VERSION ""

NS_ :

BS_:

BU_:

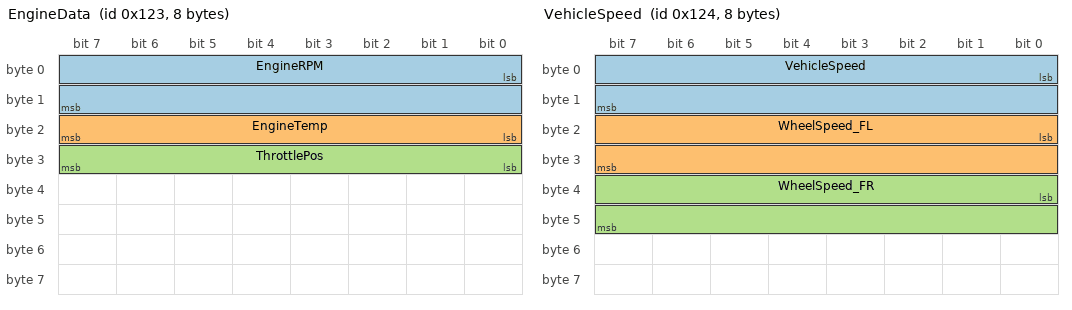
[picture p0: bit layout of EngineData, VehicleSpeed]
BO_ 291 EngineData: 8 Vector__XXX
 SG_ EngineRPM : 0|16@1+ (0.25,0) [0|16383.75] "rpm" Vector__XXX
 SG_ EngineTemp : 16|8@1+ (0.75,-40) [-40|148.75] "degC" Vector__XXX
 SG_ ThrottlePos : 24|8@1+ (0.392157,0) [0|100] "%" Vector__XXX

BO_ 292 VehicleSpeed: 8 Vector__XXX
 SG_ VehicleSpeed : 0|16@1+ (0.01,0) [0|655.35] "km/h" Vector__XXX
 SG_ WheelSpeed_FL : 16|16@1+ (0.01,0) [0|655.35] "km/h" Vector__XXX
 SG_ WheelSpeed_FR : 32|16@1+ (0.01,0) [0|655.35] "km/h" Vector__XXX

BO_ 293 BrakeData: 8 Vector__XXX
 SG_ BrakePressure : 0|8@1+ (1,0) [0|255] "bar" Vector__XXX
 SG_ BrakeActive : 8|1@1+ (1,0) [0|1] "" Vector__XXX
